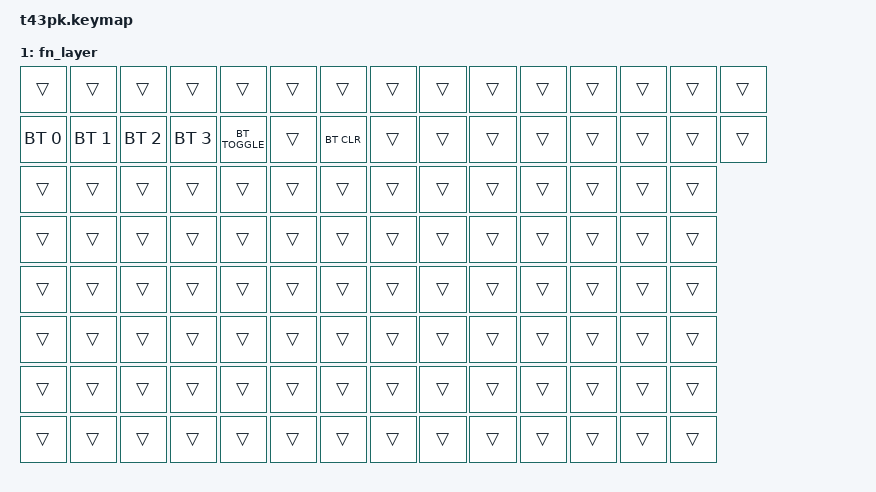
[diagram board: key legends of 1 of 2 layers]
#include <behaviors.dtsi>
#include <dt-bindings/zmk/keys.h>
#include <dt-bindings/zmk/bt.h> // 引入蓝牙宏定义


//Esc     AccessIBM   vol-    vol+    mute                power   PrtSc    ScrLK   Pause   Insert  Home    PgUp
//F1      F2      F3      F4	  	F5   F6   F7   F8    F9        F10     F11     F12      del      end     PgDn 
//`       1    2    3             4      5   6    7      8      9       0           -     =           Backspace  
//TAB       Q     W    E      R      T       Y      U       I      O       P          [       ]        \   
//capsLock    A     S    D      F      G       H      J       K      L       ;      '                     ENTER     
//Shift        Z      X     C     V      B       N      M       ,      .       /                          Shift 
//Fn   LCTL   LALT                     SPACE                   RALT   RCTL           pageLeft    up   pageright  
//                            MLeft   MMidlle  MRight                               left       down      right    

/ {
    keymap {
        compatible = "zmk,keymap";
        default_layer {
            bindings = <
            //  C0          C1              C2              C3              C4              C5              C6              C7               
                &kp N/A     &kp RCTRL       &kp N/A         &kp N/A         &kp N/A         &kp LCTRL       &kp N/A         &kp N/A         //R0 
                &kp RALT    &kp N/A         &kp PSCRN       &kp SLCK        &kp N/A         &kp N/A         &kp LALT        &kp N/A         //R1
                &kp N/A     &kp RSHIFT      &kp N/A         &kp N/A         &kp LSHIFT      &kp N/A         &kp N/A         &kp N/A         //R2
                &kp LEFT    &kp PAUSE_BREAK &kp END         &kp N/A         &kp N/A         &kp HOME        &kp UP          &kp N/A         //R3
                &kp N/A     &kp Z           &kp N1          &kp Q           &kp TAB         &kp backtick    &kp ESC         &kp A           //R4    backtick
                &kp pageR   &kp PageL       &kp pagedown    &kp N/A         &kp N/A         &kp pageup      &kp N/A         &kp N/A         //R5    page 相关未找到
                &kp RIGHT   &kp N/A         &kp F12         &kp N/A         &kp N/A         &kp INSERT      &kp N/A         &kp N/A         //R6
                &kp DOWN    &kp N/A         &kp F11         &kp K_VOL_UP    &kp K_VOL_DOWN  &kp DEL         &kp AccessIBM   &kp K_MUTE      //R7    AccessIBM 
                &kp SLASH   &kp N/A         &kp N0          &kp P           &kp LBKT        &kp MINUS       &kp SQT         &kp SEMI        //R8
                &kp N/A     &kp C           &kp N3          &kp E           &kp F3          &kp F2          &kp F4          &kp D           //R9
                &kp N/A     &kp Period      &kp N9          &kp O           &kp F7          &kp F8          &kp N/A         &kp L           //R10
                &kp B       &kp V           &kp N4          &kp R           &kp T           &kp N5          &kp G           &kp F           //R11
                &kp N/A     &kp X           &kp N2          &kp W           &kp CAPS        &kp F1          &kp N/A         &kp S           //R12
                &kp SPACE   &kp ENTER       &kp F10         &kp N/A         &kp BACKSPACE   &kp F9          &kp F5          &kp BACKSLASH   //R13
                &kp N/A     &kp COMMA       &kp N8          &kp I           &kp RBKT        &kp EQUAL       &kp F6          &kp K           //R14
                &kp N       &kp M           &kp N7          &kp U           &kp Y           &kp N6          &kp H           &kp J           //R15
                &kp N/A     &kp N/A         &kp N/A         &kp N/A         &kp N/A         &kp N/A         &kp N/A         &kp N/A         //R16
            >;
        };

        // Layer 1: Fn 功能层 (Fn Layer) - 蓝牙控制在此层实现
        fn_layer {
            bindings = <
                // R0 - 保持透传 (Transparent)
                &trans            &trans          &trans           &trans           &trans           &trans          &trans          &trans          &trans          &trans          &trans          &trans          &trans          &trans          &trans
                // R1 (F区) - 蓝牙功能
                &bt BT_SEL 0      &bt BT_SEL 1    &bt BT_SEL 2     &bt BT_SEL 3     &bt BT_TOGGLE    &trans          &bt BT_CLR      &trans          &trans          &trans          &trans          &trans          &trans          &trans          &trans
                // F1: 切换到设备 1 (BT_SEL 0)
                // F2: 切换到设备 2 (BT_SEL 1)
                // F3: 切换到设备 3 (BT_SEL 2)
                // F4: 切换到设备 4 (BT_SEL 3)
                // F5: 开启/关闭蓝牙 (BT_TOGGLE)
                // F6: 透传 (Trans)
                // F7: 清空蓝牙配对信息 (BT_CLR)
                
                // R2 及其以下 - 保持透传
                &trans            &trans          &trans           &trans           &trans           &trans          &trans          &trans          &trans          &trans          &trans          &trans          &trans          &trans
                &trans            &trans          &trans           &trans           &trans           &trans          &trans          &trans          &trans          &trans          &trans          &trans          &trans          &trans
                &trans            &trans          &trans           &trans           &trans           &trans          &trans          &trans          &trans          &trans          &trans          &trans          &trans          &trans
                &trans            &trans          &trans           &trans           &trans           &trans          &trans          &trans          &trans          &trans          &trans          &trans          &trans          &trans
                &trans            &trans          &trans           &trans           &trans           &trans          &trans          &trans          &trans          &trans          &trans          &trans          &trans          &trans
                &trans            &trans          &trans           &trans           &trans           &trans          &trans          &trans          &trans          &trans          &trans          &trans          &trans          &trans
            >;
        };
    };
};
